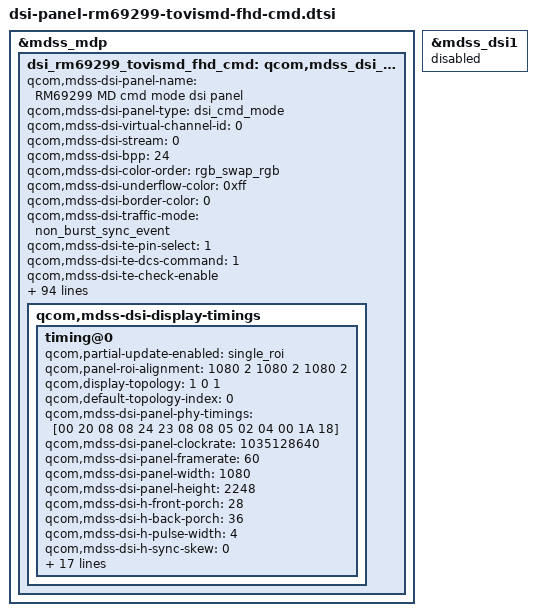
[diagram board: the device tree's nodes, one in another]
/* Copyright (c) 2014, Code Aurora Forum. All rights reserved.
 *
 * This program is free software; you can redistribute it and/or modify
 * it under the terms of the GNU General Public License version 2 and
 * only version 2 as published by the Free Software Foundation.
 *
 * This program is distributed in the hope that it will be useful,
 * but WITHOUT ANY WARRANTY; without even the implied warranty of
 * MERCHANTABILITY or FITNESS FOR A PARTICULAR PURPOSE.  See the
 * GNU General Public License for more details.
 */

&mdss_mdp {
    dsi_rm69299_tovismd_fhd_cmd: qcom,mdss_dsi_rm69299_tovismd_fhd_cmd {
		qcom,mdss-dsi-panel-name = "RM69299 MD cmd mode dsi panel";
		qcom,mdss-dsi-panel-type = "dsi_cmd_mode";
		qcom,mdss-dsi-virtual-channel-id = <0>;
		qcom,mdss-dsi-stream = <0>;
		qcom,mdss-dsi-bpp = <24>;
		qcom,mdss-dsi-color-order = "rgb_swap_rgb";
		qcom,mdss-dsi-underflow-color = <0xff>;
		qcom,mdss-dsi-border-color = <0>;
		qcom,mdss-dsi-traffic-mode = "non_burst_sync_event";
		qcom,mdss-dsi-te-pin-select = <1>;
		qcom,mdss-dsi-te-dcs-command = <1>;
		qcom,mdss-dsi-te-check-enable;
		qcom,mdss-dsi-te-using-te-pin;
		qcom,mdss-dsi-lane-map = "lane_map_0123";
		qcom,mdss-dsi-bllp-eof-power-mode;
		qcom,mdss-dsi-bllp-power-mode;
		qcom,mdss-dsi-lane-0-state;
		qcom,mdss-dsi-lane-1-state;
		qcom,mdss-dsi-lane-2-state;
		qcom,mdss-dsi-lane-3-state;
		qcom,mdss-dsi-reset-sequence = <1 10>, <0 2>, <1 10>;
		qcom,mdss-dsi-dma-trigger = "trigger_sw";
		qcom,mdss-dsi-mdp-trigger = "none";
		qcom,mdss-dsi-wr-mem-start = <0x2c>;
		qcom,mdss-dsi-wr-mem-continue = <0x3c>;
		qcom,mdss-dsi-lp11-init;
		qcom,mdss-dsi-tx-eot-append;
		qcom,ulps-enabled;
		qcom,mdss-dsi-panel-hdr-enabled;
		qcom,mdss-dsi-panel-hdr-color-primaries = <14880 15935 32435 16555 14945 30910 7790 3415>;
		qcom,mdss-dsi-panel-peak-brightness = <5643000>;
		qcom,mdss-dsi-panel-blackness-level = <6134>;
		qcom,esd-check-enabled;
		qcom,mdss-dsi-panel-status-check-mode = "te_signal_check";

		lge,blmap = <
			0
			3 3 3 3 3 3 3 3 3 3 3 3 3 4 4 4 4 4 4 5
			5 5 5 5 5 5 6 6 6 6 6 6 7 7 7 7 7 8 8 9
			9 9 10 10 11 11 11 12 12 13 13 13 14 14 15 15 15 16 16 17
			17 18 19 19 20 21 22 23 23 24 25 26 27 27 28 29 30 30 31 32
			33 34 36 37 36 37 39 40 42 43 44 46 47 49 50 51 53 54 55 57
			58 60 61 62 64 65 67 68 70 71 73 75 76 78 80 82 83 85 87 88
			90 92 93 95 97 98 100 102 104 105 107 109 110 112 114 117 119 121 124 126
			128 130 132 135 137 139 142 144 146 148 151 153 155 158 160 162 165 167 170 173
			176 180 183 186 189 192 195 199 202 205 208 211 214 218 221 224 227 230 233 237
			240 243 246 250 255 259 263 267 272 276 280 285 289 293 298 302 306 310 315 319
			323 328 332 336 340 345 349 354 359 364 370 375 380 385 390 395 401 406 411 416
			421 426 432 437 442 447 452 457 463 468 473 478 484 491 497 504 510 516 523 529
			536 542 548 555 561 567 574 580 587 593 599 606 612 619 625 626 627 628 629 630
			631 632 632 633 634 635 636 637 638 639 640 641 642 643 644 645 646 647 647 648
			649 650 651 652 653 654 657 660 663 666 669 672 675 678 682 686 690 694 698 702
			706 710 712 714 716 718 721 723 725 727 729 731 733 735 737 740 742 744 746 748
			752 756 761 765 769 773 778 782 786 790 795 799 803 808 813 818 823 828 833 839
			844 849 854 859 864 869 877 885 893 901 910 918 926 934 942 950 958 966 974 982
			991 999 1007 1015 1023
			>;
		lge,blmap-ve = <
			0
			3 3 3 3 3 3 3 3 3 3 3 3 4 4 4 4 4 5 5 5
			5 5 6 6 6 6 6 6 7 7 7 7 7 8 8 8 9 9 10 11
			12 12 13 14 14 15 16 17 17 18 19 20 20 21 22 22 23 24 25 25
			26 27 29 30 31 32 34 35 36 37 39 40 41 42 44 45 46 47 49 50
			51 53 56 58 56 58 61 63 66 68 71 73 76 78 81 83 86 88 91 93
			96 98 101 103 106 108 111 113 116 118 121 123 126 128 131 134 136 139 141 144
			147 149 152 154 157 159 162 165 167 170 172 175 177 180 184 188 192 196 200 204
			209 211 215 219 223 227 232 236 240 244 248 252 256 260 264 268 272 276 282 288
			294 300 306 312 318 324 330 336 342 348 354 359 365 371 377 383 389 395 401 407
			413 419 425 432 440 447 455 462 470 477 484 492 499 507 514 521 529 536 544 551
			559 566 573 581 588 596 603 610 617 624 631 638 645 652 659 666 673 680 687 695
			702 709 716 723 730 737 744 751 758 765 772 779 789 798 808 817 827 837 846 856
			865 875 885 894 904 914 923 933 942 952 962 971 981 990 1000 1000 1000 1000 1000 1000
			1000 1000 1000 1000 1000 1000 1000 1000 1000 1000 1000 1000 1000 1000 1000 1000 1000 1000 1000 1000
			1000 1000 1000 1000 1000 1000 1000 1001 1001 1002 1002 1002 1003 1003 1004 1004 1005 1005 1006 1006
			1007 1007 1007 1007 1008 1008 1008 1008 1008 1008 1009 1009 1009 1009 1009 1009 1010 1010 1010 1010
			1010 1010 1010 1011 1011 1011 1011 1011 1011 1012 1012 1012 1012 1012 1013 1013 1013 1014 1014 1014
			1014 1015 1015 1015 1016 1016 1016 1017 1017 1017 1018 1018 1019 1019 1019 1020 1020 1020 1021 1021
			1022 1022 1022 1023 1023
			>;
		lge,blmap-ex = <
			1
			1 1 1 1 1 1 1 1 1 1 1 1 1 1 2 2 2 2 2 3
			3 3 3 3 4 4 4 4 4 5 5 5 5 5 5 5 5 6 6 7
			7 8 8 9 9 10 10 11 11 12 12 13 13 14 14 15 15 16 16 17
			17 18 18 19 19 20 20 21 21 22 22 23 23 23 23 23 24 25 26 27
			28 29 30 31 32 33 34 35 36 37 38 39 40 40 40 40 40 40 40 40
			41 42 43 44 45 46 47 48 49 50 51 52 52 52 52 53 53 54 54 55
			55 56 56 57 57 58 58 59 59 60 60 61 61 62 62 62 62 62 62 62
			63 64 65 66 67 68 69 70 71 72 73 74 75 76 77 78 79 80 80 80
			80 80 80 80 80 80 80 80 80 80 80 80 80 80 80 80 80 80 80 80
			80 80 80 80 80 80 80 80 80 80 80 80 80 80 80 80 80 80 80 80
			80 80 80 80 80 80 80 80 80 80 80 80 80 80 80 80 80 80 80 80
			80 80 80 80 80 80 80 80 80 80 80 80 80 80 80 80 80 80 80 80
			80 80 80 80 80 80 80 80 80 80 80 80 80 80 80
		>;
		lge,blmap-hdr = <
			0
			3 3 3 3 3 3 3 3 3 3 3 3 4 4 4 4 4 5 5 5
			5 5 6 6 6 6 6 6 7 7 7 7 7 8 8 8 9 9 10 10
			11 12 12 13 13 14 15 15 16 16 17 18 18 19 19 20 21 21 22 22
			23 24 25 27 28 29 30 31 33 34 35 36 38 39 40 41 42 44 45 46
			47 49 51 53 52 54 56 58 60 62 64 66 68 70 72 74 76 78 80 82
			84 86 88 90 92 94 96 98 101 103 106 108 111 113 116 118 121 123 126 128
			131 133 136 138 141 143 146 148 151 153 156 158 161 163 167 170 174 177 181 185
			188 191 194 198 202 205 209 212 216 220 223 227 230 234 238 241 245 248 253 258
			263 269 274 279 284 289 295 300 305 310 316 321 326 331 336 342 347 352 357 362
			368 373 378 385 392 398 405 412 419 425 432 439 446 452 459 466 473 479 486 493
			500 506 513 520 527 533 540 547 554 561 568 574 581 588 595 602 609 616 623 629
			636 643 650 657 664 671 678 684 691 698 705 712 721 729 738 746 755 763 772 780
			789 797 806 814 823 831 840 848 857 865 874 882 891 899 908 908 909 909 909 909
			910 910 910 910 911 911 911 911 912 912 912 912 913 913 913 913 914 914 914 914
			915 915 915 915 916 916 916 917 917 918 918 918 919 919 920 922 923 925 926 927
			929 930 931 932 933 933 934 935 936 937 938 938 939 940 941 942 943 943 944 945
			946 947 948 949 950 951 952 953 954 955 956 957 958 960 961 963 964 966 967 969
			970 972 973 975 976 978 980 983 985 987 990 992 995 997 999 1002 1004 1006 1009 1011
			1014 1016 1018 1021 1023
		>;
		qcom,mdss-pan-physical-width-dimension = <68>;
		qcom,mdss-pan-physical-height-dimension = <142>;

		qcom,mdss-dsi-t-clk-post = <0x18>;
		qcom,mdss-dsi-t-clk-pre = <0x1A>;

		lge,use-ambient;
		lge,aod-interface-data = "semi-partial", "semi-partial", "semi-partial";
		lge,mdss-dsi-nolp-command = [
			15 01 00 00 00 00 02 FE D0
			15 01 00 00 00 00 02 5C C0
			15 01 00 00 00 00 02 FE 00
			05 01 00 00 20 00 01 28
			15 01 00 00 00 00 02 FE 20
			15 01 00 00 00 00 02 72 11
			15 01 00 00 00 00 02 FE 00
			15 01 00 00 00 00 02 53 E0
			05 01 00 00 00 00 01 13
			05 01 00 00 00 00 01 38
			05 01 00 00 00 00 01 29
		];
		lge,mdss-dsi-nolp-command-state = "dsi_lp_mode";

		lge,mdss-dsi-aod-area-command = [
			15 01 00 00 00 00 02 FE 00
			39 01 00 00 00 00 05 30 00 00 04 37
		];
		lge,mdss-dsi-aod-area-command-state = "dsi_lp_mode";

		lge,mdss-dsi-lp2-command = [
			15 01 00 00 00 00 02 FE 40
			15 01 00 00 00 00 02 4E 01
			15 01 00 00 00 00 02 FE D0
			15 01 00 00 00 00 02 5C D0
			15 01 00 00 00 00 02 FE 00
			05 01 00 00 20 00 01 28
			15 01 00 00 00 00 02 FE 20
			15 01 00 00 00 00 02 72 16
			15 01 00 00 00 00 02 FE 00
			15 01 00 00 00 00 02 53 20
			05 01 00 00 00 00 01 12
			05 01 00 00 00 00 01 39
			05 01 00 00 00 00 01 29
		];
		lge,mdss-dsi-lp2-command-state = "dsi_lp_mode";

		lge,use-color-manager;
		lge,color-manager-default-status = <1>;
		lge,mdss-dsi-color-manager-mode-table = <0 1>, <1 1>, <2 1>, <3 1>;
		lge,digital-gamma-absent;
		lge,true-view-supported;
		lge,mdss-dsi-disp-ctrl-command-1 = [
			15 01 00 00 00 00 02 FE 00
			15 01 00 00 00 00 02 53 E0
			15 01 00 00 00 00 02 5C 00
			15 01 00 00 00 00 02 FE 80
			15 01 00 00 00 00 02 05 00
			15 01 00 00 00 00 02 FE 12
			15 01 00 00 00 00 02 84 08
			15 01 00 00 00 00 02 FE 00
		];
		lge,mdss-dsi-disp-ctrl-command-1-state = "dsi_lp_mode";
		lge,mdss-dsi-disp-ctrl-command-2 = [
			15 01 00 00 00 00 02 FE 40
			15 01 00 00 00 00 02 79 00
			15 01 00 00 00 00 02 FE 00
		];
		lge,mdss-dsi-disp-ctrl-command-2-state = "dsi_lp_mode";

		lge,color-mode-cmds-dummy = [
			/* CE setting */
			15 00 00 00 00 00 02 FE 00
			15 00 00 00 00 00 02 5A 0B
			/* HUE, SAT enable/disable */
			15 00 00 00 00 00 02 FE 80
			15 00 00 00 00 00 02 00 4F
			/* CE gain */
			15 00 00 00 00 00 02 08 E0
			15 00 00 00 00 00 02 09 00
			15 00 00 00 00 00 02 0A ED
			15 00 00 00 00 00 02 0B 00
			15 00 00 00 00 00 02 0C 00
			15 00 00 00 00 00 02 0D 00
			15 00 00 00 00 00 02 0E CD
			15 00 00 00 00 00 02 0F 0F
			15 00 00 00 00 00 02 14 00
			15 00 00 00 00 00 02 15 A6
			15 00 00 00 00 00 02 16 F5
			15 00 00 00 00 00 02 17 09
			15 00 00 00 00 00 02 18 7E
			15 00 00 00 00 00 02 19 00
			15 00 00 00 00 00 02 1A 68
			15 00 00 00 00 00 02 1B 03
			/* Default CM */
			15 00 00 00 00 00 02 FE 10
			15 00 00 00 00 00 02 00 D9
			15 00 00 00 00 00 02 01 67
			15 00 00 00 00 00 02 02 00
			15 00 00 00 00 00 02 03 21
			15 00 00 00 00 00 02 04 20
			15 00 00 00 00 00 02 05 81
			15 00 00 00 00 00 02 06 FF
			15 00 00 00 00 00 02 07 17
			15 00 00 00 00 00 02 08 80
			15 00 00 00 00 00 02 09 01
			15 00 00 00 00 00 02 0A 80
			15 00 00 00 00 00 02 0B 80
			15 00 00 00 00 00 02 0C FF
			15 00 00 00 00 00 02 0D 07
			15 00 00 00 00 00 02 2F 19
			15 00 00 00 00 00 02 FE D0
			15 00 00 00 00 00 02 80 00
			15 01 00 00 00 00 02 FE 00
		];
		lge,color-mode-cmds-dummy-state = "dsi_lp_mode";

		lge,use-color-manager-lut;
		lge,cm-lut-screen-mode-set-name = "def", "cin", "pho", "web", "spo", "gam", "exp";
		lge,cm-lut-screen-mode-set-cnt = <38>;
		lge,cm-lut-screen-mode-set = [
			00 0B 80 4F E0 00 ED 00 00 00 CD 0F 00 A6 F5 09 7E 00 68 03 10 D9 67 00 21 20 81 FF 17 80 01 80 80 FF 07 19 D0 00 /* def */
			00 0B 80 4F CC 0E ED E0 DF DD 48 00 00 A2 F5 0F FE 02 68 03 10 69 97 06 35 30 00 6B 97 02 01 58 00 F2 06 1C D0 00 /* cin */
			00 0B 80 4F CD 0E EE E0 DE DD 48 00 00 A4 F5 0F FE 02 68 03 10 FF 67 8D 47 E0 06 6E 46 03 38 30 00 44 06 1C D0 00 /* pho */
			00 0B 80 4F CD 0E 0F E0 DE DD 68 00 00 A2 F5 0F FE 02 68 03 10 D6 65 20 41 C0 04 17 07 03 27 40 0B 1E 06 1C D0 00 /* web */
			00 0B 80 4F E0 00 ED 00 00 00 CD 0F 00 A6 F5 09 7E 00 68 03 10 44 07 00 21 00 00 87 97 80 00 08 80 FF 07 1C D0 00 /* spo */
			00 0B 80 4F F1 21 FE 33 22 22 CD 0F 00 A6 F5 09 7E 00 68 03 10 B6 07 00 1F 00 00 D9 97 80 00 00 00 FF 07 19 D0 00 /* gam */
			00 0B 80 4F E0 00 ED 00 00 00 CD 0F 00 A6 F5 09 7E 00 68 03 10 D9 67 00 21 20 81 FF 17 80 01 80 80 FF 07 19 D0 00 /* exp */
		];

		lge,cm-lut-saturation-cnt = <20>;
		lge,cm-lut-saturation = [
			00 0B 80 4F CD CD CC CC CC DC 00 00 00 A6 F5 09 7E 00 68 03
			00 0B 80 4F DF DF ED EE EE EE 00 00 00 A6 F5 09 7E 00 68 03
			00 0B 80 4F E0 00 ED 00 00 00 CD 0F 00 A6 F5 09 7E 00 68 03
			00 0B 80 4F F1 21 FE 33 22 22 CD 0F 00 A6 F5 09 7E 00 68 03
			00 0B 80 4F 13 33 0F 44 55 33 EF 0F 00 A6 F5 09 7E 00 68 03
		];

		lge,cm-lut-rgb-hue-cnt = <18>;
		lge,cm-lut-rgb-hue = [
			10 B7 A5 00 5F 91 08 76 27 00 01 A0 0F 46 06 19 D0 00 /*Hue1 CT1~CT5*/
			10 27 A6 00 5F 91 08 76 27 00 01 A0 0F AC 06 19 D0 00
			10 97 A6 00 5F 91 08 76 27 00 01 A0 0F 06 07 19 D0 00
			10 97 A6 00 5F 91 08 1F 27 00 01 A0 0F F9 06 19 D0 00
			10 97 A6 00 5F 91 08 B6 26 00 01 A0 0F F6 06 19 D0 00
			10 51 86 00 C7 A0 04 B4 27 00 01 18 08 C0 06 19 D0 00 /*Hue2 CT1~CT5*/
			10 D1 86 00 C7 A0 04 B4 27 00 01 18 08 2B 07 19 D0 00
			10 31 87 00 C7 A0 04 B4 27 00 01 18 08 80 07 19 D0 00
			10 31 87 00 C7 A0 04 64 27 00 01 18 08 78 07 19 D0 00
			10 31 87 00 C7 A0 04 00 27 00 01 18 08 70 07 19 D0 00
			10 F1 06 00 1D 00 80 FF 87 80 00 00 00 30 07 19 D0 00 /*Hue3 CT1~CT5*/
			10 67 07 00 1E 00 80 FF 97 80 00 00 00 99 07 19 D0 00
			10 D9 67 00 21 20 81 FF 17 80 01 80 80 FF 07 19 D0 00
			10 E1 07 00 20 00 80 B7 97 80 00 00 00 F5 07 19 D0 00
			10 E1 07 00 21 00 80 4C 97 80 00 00 00 F1 07 19 D0 00
			10 7A 86 0A 02 10 80 94 D7 06 4F 30 00 EA 06 19 D0 00 /*Hue4 CT1~CT5*/
			10 F6 86 0A 02 10 80 94 D7 06 4F 30 00 58 07 19 D0 00
			10 56 87 0A 02 10 80 94 D7 06 4F 30 00 AE 07 19 D0 00
			10 56 87 0A 02 10 80 44 D7 06 4F 30 00 A8 07 19 D0 00
			10 56 87 0A 02 10 80 DB D6 06 4F 30 00 9E 07 19 D0 00
			10 E8 85 13 01 28 80 37 B7 0C 94 40 00 A8 06 19 D0 00 /*Hue5 CT1~CT5*/
			10 60 86 13 01 28 80 37 B7 0C 94 40 00 10 07 19 D0 00
			10 C8 86 13 01 28 80 37 B7 0C 94 40 00 68 07 19 D0 00
			10 C8 86 13 01 28 80 E7 B6 0C 94 40 00 60 07 19 D0 00
			10 C8 86 13 01 28 80 82 B6 0C 94 40 00 5E 07 19 D0 00
		];

		lge,cm-lut-sharpness-cnt = <1>;
		lge,cm-lut-sharpness = [08 12 1C 26 30];

		lge,cm-lut-trueview-cnt = <18>;
		lge,cm-lut-trueview = [
			10 D9 67 00 21 20 81 FF 17 80 01 80 80 FF 07 19 D0 00
			10 74 07 00 20 00 00 A8 A7 80 00 08 00 FF 07 1C D0 00
			10 87 07 00 20 00 80 BB 97 80 00 00 00 FF 07 1C D0 00
			10 9C 07 00 1F 00 80 CB 97 80 00 00 00 FF 07 1C D0 00
			10 B6 07 00 1F 00 00 D9 97 80 00 00 00 FF 07 1C D0 00
			10 C1 07 00 1F 00 80 E5 97 80 00 08 00 FF 07 1C D0 00
			10 D9 67 00 21 20 81 FF 17 80 01 80 80 FF 07 1C D0 00
			10 E2 07 00 1E 00 80 F4 97 80 00 00 00 E0 07 1C D0 00
			10 E3 07 00 1E 00 00 E8 97 80 00 08 00 BB 07 1C D0 00
			10 E3 07 00 1E 00 00 E3 97 80 00 00 00 A6 07 1C D0 00
			10 E3 07 80 1D 00 00 DA 97 80 00 08 00 7D 07 1C D0 00
			10 E4 07 80 1D 00 80 C7 97 80 00 08 80 61 07 1C D0 00
			10 E4 07 00 1D 00 00 C9 97 80 00 08 00 51 07 1C D0 00
			10 E5 07 00 1C 00 80 BA 87 80 00 08 00 33 07 1C D0 00
			10 E5 07 00 1C 00 80 A5 87 80 00 00 00 17 07 1C D0 00
			10 E6 07 00 1C 00 80 94 87 80 00 00 00 EE 06 1C D0 00
			10 E6 07 80 1C 00 80 82 87 80 00 00 00 D5 06 1C D0 00
			10 E7 07 00 1B 00 80 6C 87 80 00 00 00 AA 06 1C D0 00
			10 E7 07 00 1B 00 00 5F 87 80 00 08 00 8D 06 1C D0 00
			10 E7 07 00 1B 00 00 4D 87 80 00 08 00 71 06 1C D0 00
			10 E8 07 00 1A 00 00 3E 87 80 00 08 00 53 06 1C D0 00
			10 E8 07 00 1A 00 00 31 87 80 00 08 00 33 06 1C D0 00
			10 E9 07 00 1A 00 80 22 87 80 00 00 00 19 06 1C D0 00
			10 E9 07 00 19 00 00 1D 87 80 00 08 00 07 06 1C D0 00
			10 EA 07 00 19 00 00 12 77 80 00 08 00 E4 05 1C D0 00
			10 EA 07 00 19 00 80 09 77 80 00 08 00 D6 05 1C D0 00
			10 EA 07 00 19 00 00 FC 76 80 00 08 00 BF 05 1C D0 00
			10 29 97 06 35 30 00 4B 97 02 01 58 00 FC 06 1C D0 00
			10 49 97 06 35 30 00 5B 97 02 01 58 00 F7 06 1C D0 00
			10 69 97 06 35 30 00 6B 97 02 01 58 00 F2 06 1C D0 00
			10 69 97 06 35 30 00 67 97 02 01 58 00 D5 06 1C D0 00
			10 69 97 06 35 30 00 5B 97 02 01 58 00 BD 06 1C D0 00
			10 FA 67 8D 47 E0 06 7E 46 03 38 30 00 70 06 1C D0 00
			10 FB 67 8D 47 E0 06 70 46 03 38 30 00 54 06 1C D0 00
			10 FF 67 8D 47 E0 06 6E 46 03 38 30 00 44 06 1C D0 00
			10 FF 67 8D 47 E0 06 62 46 03 38 30 00 24 06 1C D0 00
			10 FF 67 8D 47 E0 06 59 46 03 38 30 00 0A 06 1C D0 00
			10 96 65 20 41 C0 04 07 07 03 27 40 0B 35 06 1C D0 00
			10 B0 65 20 41 C0 04 10 07 03 27 40 0B 28 06 1C D0 00
			10 D6 65 20 41 C0 04 17 07 03 27 40 0B 1E 06 1C D0 00
			10 D6 65 20 41 C0 04 06 07 03 27 40 0B FB 05 1C D0 00
			10 D6 65 20 41 C0 04 01 07 03 27 40 0B E5 05 1C D0 00
		];

		/* Video Enahnacement */
		lge,mdss-dsi-ve-on-command = [
			15 01 00 00 00 00 02 FE 00
			15 01 00 00 00 00 02 6A A8
		];
		lge,mdss-dsi-ve-on-command-state = "dsi_lp_mode";

		lge,mdss-dsi-ve-off-command = [
			15 01 00 00 00 00 02 FE 00
			15 01 00 00 00 00 02 6A 50
		];
		lge,mdss-dsi-ve-off-command-state = "dsi_lp_mode";

		lge,disp-br-ctrl-ext-supported;
		lge,ddic-dsi-br-ctrl-ext-command = [
			15 01 00 00 00 00 02 FE 70
			15 01 00 00 00 00 02 A9 00
			15 01 00 00 00 00 02 FE 00
		];
		lge,ddic-dsi-br-ctrl-ext-command-state = "dsi_lp_mode";

		qcom,mdss-dsi-display-timings {
			timing@0{
				qcom,partial-update-enabled = "single_roi";
				qcom,panel-roi-alignment = <1080 2 1080 2 1080 2>;
				qcom,display-topology = <1 0 1>;
				qcom,default-topology-index = <0>;
				qcom,mdss-dsi-panel-phy-timings = [00 20 08 08 24 23 08 08 05 02 04 00 1A 18];
				qcom,mdss-dsi-panel-clockrate = <1035128640>;
				qcom,mdss-dsi-panel-framerate = <60>;
				qcom,mdss-dsi-panel-width = <1080>;
				qcom,mdss-dsi-panel-height = <2248>;
				qcom,mdss-dsi-h-front-porch = <28>;
				qcom,mdss-dsi-h-back-porch = <36>;
				qcom,mdss-dsi-h-pulse-width = <4>;
				qcom,mdss-dsi-h-sync-skew = <0>;
				qcom,mdss-dsi-v-back-porch = <4>;
				qcom,mdss-dsi-v-front-porch = <56>;
				qcom,mdss-dsi-v-pulse-width = <4>;
				qcom,mdss-dsi-h-left-border = <0>;
				qcom,mdss-dsi-h-right-border = <0>;
				qcom,mdss-dsi-v-top-border = <0>;
				qcom,mdss-dsi-v-bottom-border = <0>;
				qcom,mdss-mdp-transfer-time-us = <15200>;

				qcom,mdss-dsi-on-command = [
					15 00 00 00 00 00 02 FE 40
					15 00 00 00 00 00 02 05 30
					15 00 00 00 00 00 02 06 10
					15 00 00 00 00 00 02 08 30
					15 00 00 00 00 00 02 09 10
					15 00 00 00 00 00 02 0A D8
					15 00 00 00 00 00 02 0B 88
					15 00 00 00 00 00 02 0C D8
					15 00 00 00 00 00 02 0D 98
					15 00 00 00 00 00 02 0E 50
					15 00 00 00 00 00 02 0F 8C
					15 00 00 00 00 00 02 16 00
					15 00 00 00 00 00 02 20 97
					15 00 00 00 00 00 02 21 97
					15 00 00 00 00 00 02 23 13
					15 00 00 00 00 00 02 24 02
					15 00 00 00 00 00 02 26 80
					15 00 00 00 00 00 02 27 60
					15 00 00 00 00 00 02 28 55
					15 00 00 00 00 00 02 2A 40
					15 00 00 00 00 00 02 2B 60
					15 00 00 00 00 00 02 2D 29
					15 00 00 00 00 00 02 2F 23
					15 00 00 00 00 00 02 30 28
					15 00 00 00 00 00 02 31 23
					15 00 00 00 00 00 02 37 80
					15 00 00 00 00 00 02 38 68
					15 00 00 00 00 00 02 39 00
					15 00 00 00 00 00 02 46 39
					15 00 00 00 00 00 02 4E 03
					15 00 00 00 00 00 02 64 02
					15 00 00 00 00 00 02 6F 02
					15 00 00 00 00 00 02 74 23
					15 00 00 00 00 00 02 76 51
					15 00 00 00 00 00 02 78 1E
					15 00 00 00 00 00 02 80 48
					15 00 00 00 00 00 02 84 01
					15 00 00 00 00 00 02 86 06
					15 00 00 00 00 00 02 87 06
					15 00 00 00 00 00 02 88 3E
					15 00 00 00 00 00 02 89 3E
					15 00 00 00 00 00 02 8B 00
					15 00 00 00 00 00 02 8C 00
					15 00 00 00 00 00 02 90 00
					15 00 00 00 00 00 02 91 00
					15 01 00 00 00 00 02 95 00
					15 00 00 00 00 00 02 FE 60
					15 00 00 00 00 00 02 00 8C
					15 00 00 00 00 00 02 01 00
					15 00 00 00 00 00 02 02 00
					15 00 00 00 00 00 02 03 09
					15 00 00 00 00 00 02 04 00
					15 00 00 00 00 00 02 05 0A
					15 00 00 00 00 00 02 06 64
					15 00 00 00 00 00 02 07 64
					15 00 00 00 00 00 02 09 E4
					15 00 00 00 00 00 02 0A 00
					15 00 00 00 00 00 02 0B 04
					15 00 00 00 00 00 02 0C 00
					15 00 00 00 00 00 02 0D 00
					15 00 00 00 00 00 02 0E 0A
					15 00 00 00 00 00 02 0F 63
					15 00 00 00 00 00 02 10 B8
					15 00 00 00 00 00 02 12 E4
					15 00 00 00 00 00 02 13 00
					15 00 00 00 00 00 02 14 04
					15 00 00 00 00 00 02 15 00
					15 00 00 00 00 00 02 16 00
					15 00 00 00 00 00 02 17 09
					15 00 00 00 00 00 02 18 63
					15 00 00 00 00 00 02 19 B8
					15 00 00 00 00 00 02 1B E4
					15 00 00 00 00 00 02 1C 00
					15 00 00 00 00 00 02 1D 04
					15 00 00 00 00 00 02 1E 00
					15 00 00 00 00 00 02 1F 00
					15 00 00 00 00 00 02 20 08
					15 00 00 00 00 00 02 21 63
					15 00 00 00 00 00 02 22 B8
					15 00 00 00 00 00 02 24 E4
					15 00 00 00 00 00 02 25 00
					15 00 00 00 00 00 02 26 04
					15 00 00 00 00 00 02 27 00
					15 00 00 00 00 00 02 28 00
					15 00 00 00 00 00 02 29 07
					15 00 00 00 00 00 02 2A 63
					15 00 00 00 00 00 02 2B B8
					15 00 00 00 00 00 02 2F C4
					15 00 00 00 00 00 02 30 00
					15 00 00 00 00 00 02 31 04
					15 00 00 00 00 00 02 32 02
					15 00 00 00 00 00 02 33 00
					15 00 00 00 00 00 02 34 04
					15 00 00 00 00 00 02 35 64
					15 00 00 00 00 00 02 36 24
					15 00 00 00 00 00 02 38 C4
					15 00 00 00 00 00 02 39 00
					15 00 00 00 00 00 02 3A 04
					15 00 00 00 00 00 02 3B 02
					15 00 00 00 00 00 02 3D 00
					15 00 00 00 00 00 02 3F 02
					15 00 00 00 00 00 02 40 64
					15 00 00 00 00 00 02 41 24
					15 00 00 00 00 00 02 95 CE
					15 00 00 00 00 00 02 96 00
					15 00 00 00 00 00 02 97 07
					15 00 00 00 00 00 02 98 05
					15 00 00 00 00 00 02 99 00
					15 00 00 00 00 00 02 9A 0C
					15 00 00 00 00 00 02 9B 64
					15 00 00 00 00 00 02 9C 64
					15 00 00 00 00 00 02 9D 80
					15 00 00 00 00 00 02 C7 17
					15 00 00 00 00 00 02 C8 16
					15 00 00 00 00 00 02 C9 05
					15 00 00 00 00 00 02 CA 06
					15 00 00 00 00 00 02 CB 10
					15 00 00 00 00 00 02 CC 01
					15 00 00 00 00 00 02 CD 03
					15 00 00 00 00 00 02 CE 04
					15 00 00 00 00 00 02 CF 02
					15 00 00 00 00 00 02 D0 00
					15 00 00 00 00 00 02 DB 17
					15 00 00 00 00 00 02 DC 16
					15 00 00 00 00 00 02 DD 05
					15 00 00 00 00 00 02 DE 06
					15 00 00 00 00 00 02 DF 10
					15 00 00 00 00 00 02 E0 01
					15 00 00 00 00 00 02 E1 03
					15 00 00 00 00 00 02 E2 04
					15 00 00 00 00 00 02 E3 02
					15 00 00 00 00 00 02 E4 00
					15 00 00 00 00 00 02 EF 03
					15 00 00 00 00 00 02 F0 00
					15 00 00 00 00 00 02 F2 00
					15 00 00 00 00 00 02 F3 00
					15 01 00 00 00 00 02 F4 00
					15 00 00 00 00 00 02 FE 70
					15 00 00 00 00 00 02 3A FF
					15 00 00 00 00 00 02 3B FF
					15 00 00 00 00 00 02 3F FF
					15 00 00 00 00 00 02 52 80
					15 00 00 00 00 00 02 5A 24
					15 00 00 00 00 00 02 5C 26
					15 00 00 00 00 00 02 5D 0E
					15 00 00 00 00 00 02 75 06
					15 00 00 00 00 00 02 7D 31
					15 00 00 00 00 00 02 7E 4A
					15 00 00 00 00 00 02 7F 40
					15 01 00 00 00 00 02 A9 00
					15 00 00 00 00 00 02 FE D0
					15 00 00 00 00 00 02 06 0F
					15 00 00 00 00 00 02 43 C0
					15 00 00 00 00 00 02 49 01
					15 00 00 00 00 00 02 4B F0
					15 01 00 00 00 00 02 75 87
					15 00 00 00 00 00 02 FE 90
					15 00 00 00 00 00 02 12 24
					15 00 00 00 00 00 02 13 49
					15 00 00 00 00 00 02 14 92
					15 00 00 00 00 00 02 15 86
					15 00 00 00 00 00 02 16 61
					15 00 00 00 00 00 02 17 18
					15 00 00 00 00 00 02 18 24
					15 00 00 00 00 00 02 19 49
					15 00 00 00 00 00 02 1A 92
					15 00 00 00 00 00 02 1B 86
					15 00 00 00 00 00 02 1C 61
					15 00 00 00 00 00 02 1D 18
					15 00 00 00 00 00 02 1E 24
					15 00 00 00 00 00 02 1F 49
					15 00 00 00 00 00 02 20 92
					15 00 00 00 00 00 02 21 86
					15 00 00 00 00 00 02 22 61
					15 00 00 00 00 00 02 23 18
					15 00 00 00 00 00 02 97 E1
					15 00 00 00 00 00 02 A0 60
					15 00 00 00 00 00 02 A4 F7
					15 00 00 00 00 00 02 C8 08
					15 00 00 00 00 00 02 C9 6D
					15 00 00 00 00 00 02 CA 00
					15 01 00 00 00 00 02 CB 64
					15 00 00 00 00 00 02 FE A0
					15 00 00 00 00 00 02 04 80
					15 00 00 00 00 00 02 0B 33
					15 00 00 00 00 00 02 13 00
					15 00 00 00 00 00 02 16 00
					15 00 00 00 00 00 02 25 06
					15 00 00 00 00 00 02 26 10
					15 00 00 00 00 00 02 2B 15
					15 00 00 00 00 00 02 30 03
					15 00 00 00 00 00 02 33 00
					15 01 00 00 00 00 02 37 91
					15 00 00 00 00 00 02 FE E0
					15 00 00 00 00 00 02 01 52
					15 00 00 00 00 00 02 03 00
					15 00 00 00 00 00 02 04 10
					15 00 00 00 00 00 02 05 52
					15 00 00 00 00 00 02 06 52
					15 00 00 00 00 00 02 07 00
					15 00 00 00 00 00 02 08 5E
					15 00 00 00 00 00 02 09 31
					15 00 00 00 00 00 02 0A 4B
					15 00 00 00 00 00 02 0B 78
					15 00 00 00 00 00 02 0C 78
					15 00 00 00 00 00 02 0D 43
					15 00 00 00 00 00 02 0E 8C
					15 00 00 00 00 00 02 0F 06
					15 00 00 00 00 00 02 10 04
					15 00 00 00 00 00 02 11 3D
					15 00 00 00 00 00 02 C6 62
					15 00 00 00 00 00 02 C7 E0
					15 00 00 00 00 00 02 C9 40
					15 00 00 00 00 00 02 CA 21
					15 00 00 00 00 00 02 CB C8
					15 00 00 00 00 00 02 CC 2C
					15 00 00 00 00 00 02 CD F0
					15 00 00 00 00 00 02 CE 2C
					15 00 00 00 00 00 02 CF 37
					15 00 00 00 00 00 02 D1 1F
					15 00 00 00 00 00 02 D2 00
					15 00 00 00 00 00 02 D3 62
					15 00 00 00 00 00 02 D4 62
					15 00 00 00 00 00 02 D5 00
					15 00 00 00 00 00 02 D6 3D
					15 00 00 00 00 00 02 D7 37
					15 00 00 00 00 00 02 D8 00
					15 00 00 00 00 00 02 D9 34
					15 00 00 00 00 00 02 DA FA
					15 00 00 00 00 00 02 DB 2C
					15 00 00 00 00 00 02 DC 00
					15 00 00 00 00 00 02 DD 1E
					15 00 00 00 00 00 02 DE 06
					15 00 00 00 00 00 02 DF 1D
					15 00 00 00 00 00 02 E0 1E
					15 00 00 00 00 00 02 E1 28
					15 00 00 00 00 00 02 E2 1A
					15 00 00 00 00 00 02 E3 F2
					15 00 00 00 00 00 02 E4 BC
					15 00 00 00 00 00 02 E5 EE
					15 00 00 00 00 00 02 E6 FA
					15 01 00 00 00 00 02 E7 19
					15 00 00 00 00 00 02 FE 00
					15 01 00 00 00 00 02 C2 08
					05 01 00 00 00 00 01 35
					15 01 00 00 00 00 02 53 E0
					39 01 00 00 00 00 03 51 00 00
					05 01 00 00 78 00 01 11
				];
				qcom,mdss-dsi-on-command-state = "dsi_lp_mode";

				qcom,mdss-dsi-post-panel-on-command = [
					05 01 00 00 00 00 01 29
				];

				qcom,mdss-dsi-off-command = [
					05 01 00 00 00 00 01 28
					05 01 00 00 96 00 01 10
				];
				qcom,mdss-dsi-off-command-state = "dsi_lp_mode";
				qcom,mdss-dsi-h-sync-pulse = <0>;
			};
		};
	};
};
/*
&spmi_bus {
	qcom,pmi8998@3 {
		labibb: qpnp-labibb-regulator {
			status = "disabled";
		};
	};
};
*/
&mdss_dsi1 {
	status = "disabled";
};
